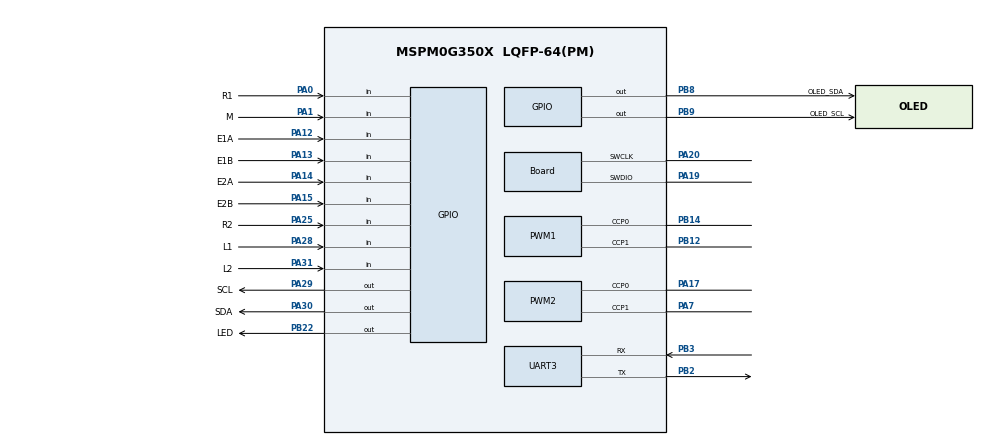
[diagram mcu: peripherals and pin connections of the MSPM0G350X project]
/**
 * @cliArgs --device "MSPM0G350X" --package "LQFP-64(PM)" --part "Default" --product "mspm0_sdk@2.00.01.00"
 * @versions {"tool":"1.20.0+3587"}
 */

/**
 * Import the modules used in this configuration.
 */
const GPIO          = scripting.addModule("/ti/driverlib/GPIO", {}, false);
const GPIO1         = GPIO.addInstance();
const GPIO2         = GPIO.addInstance();
const PWM           = scripting.addModule("/ti/driverlib/PWM", {}, false);
const PWM1          = PWM.addInstance();
const PWM2          = PWM.addInstance();
const SYSCTL        = scripting.addModule("/ti/driverlib/SYSCTL");
const SYSTICK       = scripting.addModule("/ti/driverlib/SYSTICK");
const TIMER         = scripting.addModule("/ti/driverlib/TIMER", {}, false);
const TIMER1        = TIMER.addInstance();
const TIMER2        = TIMER.addInstance();
const UART          = scripting.addModule("/ti/driverlib/UART", {}, false);
const UART1         = UART.addInstance();
const UART2         = UART.addInstance();
const UART3         = UART.addInstance();
const UART4         = UART.addInstance();
const ProjectConfig = scripting.addModule("/ti/project_config/ProjectConfig");

/**
 * Write custom configuration values to the imported modules.
 */
GPIO1.$name                              = "PORTB";
GPIO1.associatedPins.create(4);
GPIO1.associatedPins[0].$name            = "LED";
GPIO1.associatedPins[0].pin.$assign      = "PB22";
GPIO1.associatedPins[1].$name            = "OLED_SCL";
GPIO1.associatedPins[1].pin.$assign      = "PB9";
GPIO1.associatedPins[2].$name            = "OLED_SDA";
GPIO1.associatedPins[2].pin.$assign      = "PB8";
GPIO1.associatedPins[3].$name            = "KEY";
GPIO1.associatedPins[3].direction        = "INPUT";
GPIO1.associatedPins[3].internalResistor = "PULL_UP";
GPIO1.associatedPins[3].assignedPin      = "21";
GPIO1.associatedPins[3].assignedPort     = "PORTB";

const Board                       = scripting.addModule("/ti/driverlib/Board", {}, false);
Board.peripheral.$assign          = "DEBUGSS";
Board.peripheral.swclkPin.$assign = "PA20";
Board.peripheral.swdioPin.$assign = "PA19";

GPIO2.$name                               = "PORTA";
GPIO2.port                                = "PORTA";
GPIO2.associatedPins.create(12);
GPIO2.associatedPins[0].assignedPin       = "18";
GPIO2.associatedPins[0].direction         = "INPUT";
GPIO2.associatedPins[0].internalResistor  = "PULL_DOWN";
GPIO2.associatedPins[0].$name             = "KEY_BSL";
GPIO2.associatedPins[1].$name             = "L2";
GPIO2.associatedPins[1].direction         = "INPUT";
GPIO2.associatedPins[1].pin.$assign       = "PA31";
GPIO2.associatedPins[2].$name             = "L1";
GPIO2.associatedPins[2].direction         = "INPUT";
GPIO2.associatedPins[2].pin.$assign       = "PA28";
GPIO2.associatedPins[3].$name             = "M";
GPIO2.associatedPins[3].direction         = "INPUT";
GPIO2.associatedPins[3].pin.$assign       = "PA1";
GPIO2.associatedPins[4].$name             = "R1";
GPIO2.associatedPins[4].direction         = "INPUT";
GPIO2.associatedPins[4].pin.$assign       = "PA0";
GPIO2.associatedPins[5].$name             = "R2";
GPIO2.associatedPins[5].direction         = "INPUT";
GPIO2.associatedPins[5].pin.$assign       = "PA25";
GPIO2.associatedPins[6].$name             = "E2B";
GPIO2.associatedPins[6].direction         = "INPUT";
GPIO2.associatedPins[6].interruptEn       = true;
GPIO2.associatedPins[6].interruptPriority = "0";
GPIO2.associatedPins[6].polarity          = "RISE";
GPIO2.associatedPins[6].pin.$assign       = "PA15";
GPIO2.associatedPins[7].$name             = "E1A";
GPIO2.associatedPins[7].direction         = "INPUT";
GPIO2.associatedPins[7].polarity          = "RISE";
GPIO2.associatedPins[7].interruptEn       = true;
GPIO2.associatedPins[7].interruptPriority = "0";
GPIO2.associatedPins[7].pin.$assign       = "PA12";
GPIO2.associatedPins[8].$name             = "E1B";
GPIO2.associatedPins[8].direction         = "INPUT";
GPIO2.associatedPins[8].interruptEn       = true;
GPIO2.associatedPins[8].interruptPriority = "0";
GPIO2.associatedPins[8].polarity          = "RISE";
GPIO2.associatedPins[8].pin.$assign       = "PA13";
GPIO2.associatedPins[9].$name             = "E2A";
GPIO2.associatedPins[9].direction         = "INPUT";
GPIO2.associatedPins[9].interruptEn       = true;
GPIO2.associatedPins[9].interruptPriority = "0";
GPIO2.associatedPins[9].polarity          = "RISE";
GPIO2.associatedPins[9].pin.$assign       = "PA14";
GPIO2.associatedPins[10].$name            = "SCL";
GPIO2.associatedPins[10].initialValue     = "SET";
GPIO2.associatedPins[10].pin.$assign      = "PA29";
GPIO2.associatedPins[11].$name            = "SDA";
GPIO2.associatedPins[11].internalResistor = "PULL_UP";
GPIO2.associatedPins[11].pin.$assign      = "PA30";

PWM1.clockDivider                       = 8;
PWM1.timerStartTimer                    = true;
PWM1.pwmMode                            = "EDGE_ALIGN_UP";
PWM1.$name                              = "PWM_LEFT";
PWM1.peripheral.ccp0Pin.$assign         = "PB14";
PWM1.peripheral.ccp1Pin.$assign         = "PB12";
PWM1.PWM_CHANNEL_0.$name                = "ti_driverlib_pwm_PWMTimerCC0";
PWM1.PWM_CHANNEL_0.ccValue              = 1000;
PWM1.PWM_CHANNEL_1.$name                = "ti_driverlib_pwm_PWMTimerCC1";
PWM1.PWM_CHANNEL_1.ccValue              = 1000;
PWM1.ccp0PinConfig.direction            = scripting.forceWrite("OUTPUT");
PWM1.ccp0PinConfig.hideOutputInversion  = scripting.forceWrite(false);
PWM1.ccp0PinConfig.onlyInternalResistor = scripting.forceWrite(false);
PWM1.ccp0PinConfig.passedPeripheralType = scripting.forceWrite("Digital");
PWM1.ccp0PinConfig.$name                = "ti_driverlib_gpio_GPIOPinGeneric2";
PWM1.ccp1PinConfig.direction            = scripting.forceWrite("OUTPUT");
PWM1.ccp1PinConfig.hideOutputInversion  = scripting.forceWrite(false);
PWM1.ccp1PinConfig.onlyInternalResistor = scripting.forceWrite(false);
PWM1.ccp1PinConfig.passedPeripheralType = scripting.forceWrite("Digital");
PWM1.ccp1PinConfig.$name                = "ti_driverlib_gpio_GPIOPinGeneric3";

PWM2.$name                              = "PWM_RIGHT";
PWM2.clockDivider                       = 8;
PWM2.timerStartTimer                    = true;
PWM2.pwmMode                            = "EDGE_ALIGN_UP";
PWM2.peripheral.$assign                 = "TIMG7";
PWM2.peripheral.ccp0Pin.$assign         = "PA17";
PWM2.peripheral.ccp1Pin.$assign         = "PA7";
PWM2.PWM_CHANNEL_0.$name                = "ti_driverlib_pwm_PWMTimerCC2";
PWM2.PWM_CHANNEL_0.ccValue              = 1000;
PWM2.PWM_CHANNEL_1.$name                = "ti_driverlib_pwm_PWMTimerCC3";
PWM2.PWM_CHANNEL_1.ccValue              = 1000;
PWM2.ccp0PinConfig.direction            = scripting.forceWrite("OUTPUT");
PWM2.ccp0PinConfig.hideOutputInversion  = scripting.forceWrite(false);
PWM2.ccp0PinConfig.onlyInternalResistor = scripting.forceWrite(false);
PWM2.ccp0PinConfig.passedPeripheralType = scripting.forceWrite("Digital");
PWM2.ccp0PinConfig.$name                = "ti_driverlib_gpio_GPIOPinGeneric4";
PWM2.ccp1PinConfig.direction            = scripting.forceWrite("OUTPUT");
PWM2.ccp1PinConfig.hideOutputInversion  = scripting.forceWrite(false);
PWM2.ccp1PinConfig.onlyInternalResistor = scripting.forceWrite(false);
PWM2.ccp1PinConfig.passedPeripheralType = scripting.forceWrite("Digital");
PWM2.ccp1PinConfig.$name                = "ti_driverlib_gpio_GPIOPinGeneric5";

SYSCTL.clockTreeEn = true;

SYSTICK.periodEnable    = true;
SYSTICK.interruptEnable = true;
SYSTICK.systickEnable   = true;
SYSTICK.period          = 32000;

TIMER1.$name             = "TIMER_TICK";
TIMER1.timerClkDiv       = 8;
TIMER1.timerStartTimer   = true;
TIMER1.interrupts        = ["ZERO"];
TIMER1.timerMode         = "PERIODIC";
TIMER1.interruptPriority = "0";
TIMER1.timerClkPrescale  = 100;
TIMER1.timerPeriod       = "10ms";

TIMER2.$name             = "TIMER_0";
TIMER2.timerClkDiv       = 8;
TIMER2.timerClkPrescale  = 100;
TIMER2.timerPeriod       = "100 ms";
TIMER2.timerStartTimer   = true;
TIMER2.interrupts        = ["ZERO"];
TIMER2.interruptPriority = "3";
TIMER2.timerMode         = "PERIODIC";

UART1.$name              = "UART_0";
UART1.targetBaudRate     = 115200;
UART1.peripheral.$assign = "UART0";
UART1.txPinConfig.$name  = "ti_driverlib_gpio_GPIOPinGeneric0";
UART1.rxPinConfig.$name  = "ti_driverlib_gpio_GPIOPinGeneric1";

UART2.$name              = "UART_1";
UART2.targetBaudRate     = 115200;
UART2.enabledInterrupts  = ["RX"];
UART2.interruptPriority  = "0";
UART2.peripheral.$assign = "UART1";
UART2.txPinConfig.$name  = "ti_driverlib_gpio_GPIOPinGeneric6";
UART2.rxPinConfig.$name  = "ti_driverlib_gpio_GPIOPinGeneric7";

UART3.$name                            = "UART_3";
UART3.targetBaudRate                   = 115200;
UART3.enabledInterrupts                = ["RX"];
UART3.interruptPriority                = "0";
UART3.peripheral.$assign               = "UART3";
UART3.peripheral.rxPin.$assign         = "PB3";
UART3.peripheral.txPin.$assign         = "PB2";
UART3.txPinConfig.$name                = "ti_driverlib_gpio_GPIOPinGeneric8";
UART3.txPinConfig.direction            = scripting.forceWrite("OUTPUT");
UART3.txPinConfig.hideOutputInversion  = scripting.forceWrite(false);
UART3.txPinConfig.onlyInternalResistor = scripting.forceWrite(false);
UART3.txPinConfig.passedPeripheralType = scripting.forceWrite("Digital");
UART3.rxPinConfig.$name                = "ti_driverlib_gpio_GPIOPinGeneric9";
UART3.rxPinConfig.hideOutputInversion  = scripting.forceWrite(false);
UART3.rxPinConfig.onlyInternalResistor = scripting.forceWrite(false);
UART3.rxPinConfig.passedPeripheralType = scripting.forceWrite("Digital");

UART4.$name                            = "UART_2";
UART4.targetBaudRate                   = 115200;
UART4.enabledInterrupts                = ["RX"];
UART4.interruptPriority                = "0";
UART4.peripheral.$assign               = "UART2";
UART4.txPinConfig.$name                = "ti_driverlib_gpio_GPIOPinGeneric10";
UART4.txPinConfig.direction            = scripting.forceWrite("OUTPUT");
UART4.txPinConfig.hideOutputInversion  = scripting.forceWrite(false);
UART4.txPinConfig.onlyInternalResistor = scripting.forceWrite(false);
UART4.txPinConfig.passedPeripheralType = scripting.forceWrite("Digital");
UART4.rxPinConfig.$name                = "ti_driverlib_gpio_GPIOPinGeneric11";
UART4.rxPinConfig.hideOutputInversion  = scripting.forceWrite(false);
UART4.rxPinConfig.onlyInternalResistor = scripting.forceWrite(false);
UART4.rxPinConfig.passedPeripheralType = scripting.forceWrite("Digital");

ProjectConfig.deviceSpin = "MSPM0G3507";

/**
 * Pinmux solution for unlocked pins/peripherals. This ensures that minor changes to the automatic solver in a future
 * version of the tool will not impact the pinmux you originally saw.  These lines can be completely deleted in order to
 * re-solve from scratch.
 */
GPIO1.associatedPins[3].pin.$suggestSolution = "PB21";
GPIO2.associatedPins[0].pin.$suggestSolution = "PA18";
PWM1.peripheral.$suggestSolution             = "TIMA0";
TIMER1.peripheral.$suggestSolution           = "TIMG0";
TIMER2.peripheral.$suggestSolution           = "TIMA1";
UART1.peripheral.rxPin.$suggestSolution      = "PA11";
UART1.peripheral.txPin.$suggestSolution      = "PA10";
UART2.peripheral.rxPin.$suggestSolution      = "PA9";
UART2.peripheral.txPin.$suggestSolution      = "PA8";
UART4.peripheral.rxPin.$suggestSolution      = "PA22";
UART4.peripheral.txPin.$suggestSolution      = "PA21";
